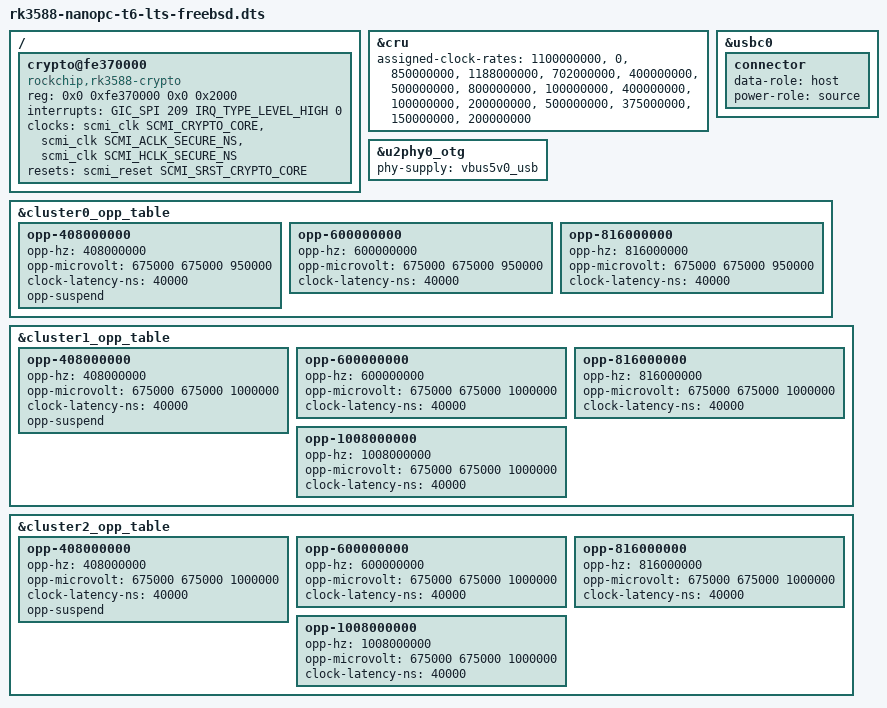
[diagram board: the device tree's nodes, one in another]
// SPDX-License-Identifier: BSD-2-Clause

/dts-v1/;

#include "rk3588-nanopc-t6-lts.dts"

/ {
	crypto@fe370000 {
		compatible = "rockchip,rk3588-crypto";
		reg = <0x0 0xfe370000 0x0 0x2000>;
		interrupts = <GIC_SPI 209 IRQ_TYPE_LEVEL_HIGH 0>;
		clocks = <&scmi_clk SCMI_CRYPTO_CORE>,
			 <&scmi_clk SCMI_ACLK_SECURE_NS>,
			 <&scmi_clk SCMI_HCLK_SECURE_NS>;
		clock-names = "core", "aclk", "hclk";
		resets = <&scmi_reset SCMI_SRST_CRYPTO_CORE>;
		reset-names = "core";
		status = "okay";
	};
};

&cru {
	/*
	 * FreeBSD does not yet drive AUPLL and this board's audio path is not
	 * adapted.  A zero rate keeps the U-Boot 24 MHz bypass state without
	 * asking the fixed-rate clock model to program Linux's 786.432 MHz rate.
	 */
	assigned-clock-rates =
		<1100000000>, <0>,
		<850000000>, <1188000000>,
		<702000000>,
		<400000000>, <500000000>,
		<800000000>, <100000000>,
		<400000000>, <100000000>,
		<200000000>, <500000000>,
		<375000000>, <150000000>,
		<200000000>;
};

&u2phy0_otg {
	phy-supply = <&vbus5v0_usb>;
};

&usbc0 {
	connector {
		data-role = "host";
		power-role = "source";
	};
};

&cluster0_opp_table {
	opp-408000000 {
		opp-hz = /bits/ 64 <408000000>;
		opp-microvolt = <675000 675000 950000>;
		clock-latency-ns = <40000>;
		opp-suspend;
	};

	opp-600000000 {
		opp-hz = /bits/ 64 <600000000>;
		opp-microvolt = <675000 675000 950000>;
		clock-latency-ns = <40000>;
	};

	opp-816000000 {
		opp-hz = /bits/ 64 <816000000>;
		opp-microvolt = <675000 675000 950000>;
		clock-latency-ns = <40000>;
	};
};

&cluster1_opp_table {
	opp-408000000 {
		opp-hz = /bits/ 64 <408000000>;
		opp-microvolt = <675000 675000 1000000>;
		clock-latency-ns = <40000>;
		opp-suspend;
	};

	opp-600000000 {
		opp-hz = /bits/ 64 <600000000>;
		opp-microvolt = <675000 675000 1000000>;
		clock-latency-ns = <40000>;
	};

	opp-816000000 {
		opp-hz = /bits/ 64 <816000000>;
		opp-microvolt = <675000 675000 1000000>;
		clock-latency-ns = <40000>;
	};

	opp-1008000000 {
		opp-hz = /bits/ 64 <1008000000>;
		opp-microvolt = <675000 675000 1000000>;
		clock-latency-ns = <40000>;
	};
};

&cluster2_opp_table {
	opp-408000000 {
		opp-hz = /bits/ 64 <408000000>;
		opp-microvolt = <675000 675000 1000000>;
		clock-latency-ns = <40000>;
		opp-suspend;
	};

	opp-600000000 {
		opp-hz = /bits/ 64 <600000000>;
		opp-microvolt = <675000 675000 1000000>;
		clock-latency-ns = <40000>;
	};

	opp-816000000 {
		opp-hz = /bits/ 64 <816000000>;
		opp-microvolt = <675000 675000 1000000>;
		clock-latency-ns = <40000>;
	};

	opp-1008000000 {
		opp-hz = /bits/ 64 <1008000000>;
		opp-microvolt = <675000 675000 1000000>;
		clock-latency-ns = <40000>;
	};
};
